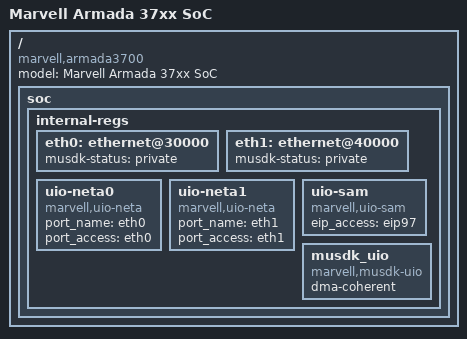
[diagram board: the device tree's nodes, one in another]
/*
 * Device Tree Include file for Marvell Armada 37xx family of SoCs.
 *
 * Copyright (C) 2016 Marvell
 *
 * Gregory CLEMENT <gregory.clement@free-electrons.com>
 *
 * This file is dual-licensed: you can use it either under the terms
 * of the GPL or the X11 license, at your option. Note that this dual
 * licensing only applies to this file, and not this project as a
 * whole.
 *
 *  a) This file is free software; you can redistribute it and/or
 *     modify it under the terms of the GNU General Public License as
 *     published by the Free Software Foundation; either version 2 of the
 *     License, or (at your option) any later version.
 *
 *     This file is distributed in the hope that it will be useful
 *     but WITHOUT ANY WARRANTY; without even the implied warranty of
 *     MERCHANTABILITY or FITNESS FOR A PARTICULAR PURPOSE.  See the
 *     GNU General Public License for more details.
 *
 * Or, alternatively
 *
 *  b) Permission is hereby granted, free of charge, to any person
 *     obtaining a copy of this software and associated documentation
 *     files (the "Software"), to deal in the Software without
 *     restriction, including without limitation the rights to use
 *     copy, modify, merge, publish, distribute, sublicense, and/or
 *     sell copies of the Software, and to permit persons to whom the
 *     Software is furnished to do so, subject to the following
 *     conditions:
 *
 *     The above copyright notice and this permission notice shall be
 *     included in all copies or substantial portions of the Software.
 *
 *     THE SOFTWARE IS PROVIDED , WITHOUT WARRANTY OF ANY KIND
 *     EXPRESS OR IMPLIED, INCLUDING BUT NOT LIMITED TO THE WARRANTIES
 *     OF MERCHANTABILITY, FITNESS FOR A PARTICULAR PURPOSE AND
 *     NONINFRINGEMENT. IN NO EVENT SHALL THE AUTHORS OR COPYRIGHT
 *     HOLDERS BE LIABLE FOR ANY CLAIM, DAMAGES OR OTHER LIABILITY
 *     WHETHER IN AN ACTION OF CONTRACT, TORT OR OTHERWISE, ARISING
 *     FROM, OUT OF OR IN CONNECTION WITH THE SOFTWARE OR THE USE OR
 *     OTHER DEALINGS IN THE SOFTWARE.
 */


/ {
	model = "Marvell Armada 37xx SoC";
	compatible = "marvell,armada3700";

	soc {
		internal-regs {
			eth0: ethernet@30000 {
				musdk-status = "private";
			};
			eth1: ethernet@40000 {
				musdk-status = "private";
			};
			uio-neta0 {
				compatible = "marvell,uio-neta";
				port_name = "eth0";
				port_access = <&eth0>;
				status = "okay";
			};
			uio-neta1 {
				compatible = "marvell,uio-neta";
				port_name = "eth1";
				port_access = <&eth1>;
				status = "okay";
			};
			uio-sam {
				compatible = "marvell,uio-sam";
				eip_access = <&eip97>;
				status = "okay";
			};
			musdk_uio {
				compatible = "marvell,musdk-uio";
				dma-coherent;
				status = "okay";
			};
		};
	};
};
